# STMP3770 register map
Vendor: Freescale Semiconductor (NXP); Series: STMP37xx; File version: 1.0
CPU: other r0p0, little endian, no MPU, no FPU, 2 interrupt priority bits
Registers are 32-bit, read-write, reset 0x0 unless marked. A register's access mark holds for its fields unless they carry their own. Offsets are from the block's base; [hi:lo] are bit positions; {n}, {i} and the like mark numbered series; 'fields as' and 'values as' point back to an identical list.

## APBH — AHB-to-APBH 桥 DMA 控制器(为 GPMI/NAND、LCDIF 等高速外设提供 DMA 通道)
Base 0x80004000
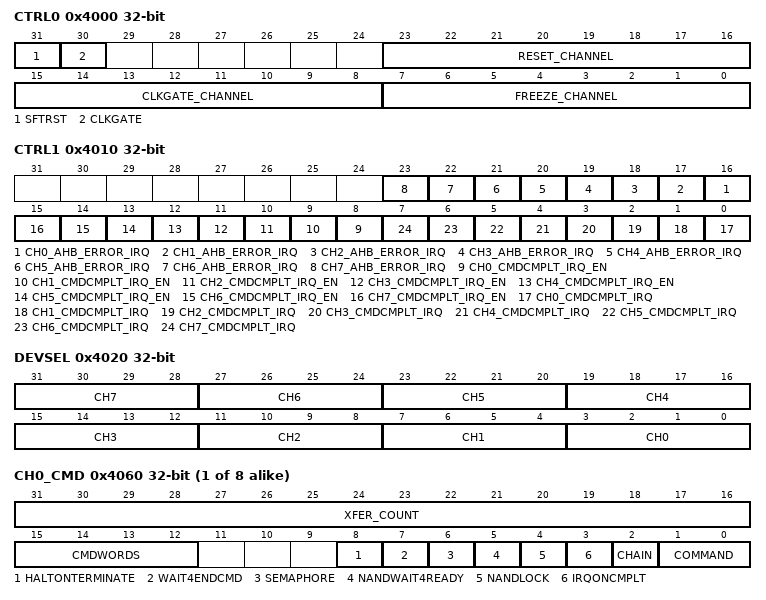
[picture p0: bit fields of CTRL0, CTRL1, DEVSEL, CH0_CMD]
0x4000 CTRL0 — AHB to APBH Bridge Control and Status Register 0
  [31] SFTRST — 软复位控制位，写1复位本模块，写0恢复正常运行。复位后所有寄存器回到默认值。
  [30] CLKGATE — 时钟门控控制位，写1关闭模块时钟以节省功耗，配置状态保持。写0恢复正常时钟供应。
  [23:16] RESET_CHANNEL — Reset Channel，8位读写字段。
    1=LCDIF; 2=SSP1; 4=SSP2; 16=ATA; 32=NAND1; 64=NAND2; 128=NAND3
  [15:8] CLKGATE_CHANNEL — Clkgate Channel，8位读写字段。
    values as RESET_CHANNEL
  [7:0] FREEZE_CHANNEL — Freeze Channel，8位读写字段。
    values as RESET_CHANNEL
0x4010 CTRL1 — AHB to APBH Bridge Control and Status Register 1
  [n+16] CH{n}_AHB_ERROR_IRQ (n=0..7) — Ch{n} Ahb Error Irq，1位读写字段。
  [n+8] CH{n}_CMDCMPLT_IRQ_EN (n=0..7) — Ch{n} Cmdcmplt Irq En，1位读写字段。
  [n] CH{n}_CMDCMPLT_IRQ (n=0..7) — Ch{n} Cmdcmplt Irq，1位读写字段。
0x4020 DEVSEL — AHB to APBH DMA Device Assignment Register
  [4n+3:4n] CH{n} ro (n=0..7) — CH{n} 通道设备分配只读值，反映复位固定的 DMA 通道到外设的分配关系。PDF 标记为 RO/保留。
{0x4040+0x70*i} CH{i}_CURCMDAR (i=0..7) ro — DMA 通道当前命令描述符物理地址(只读,DMA 引擎执行时自动更新)。
  [31:0] CMD_ADDR — 当前命令描述符的 32 位物理地址。
{0x4050+0x70*i} CH{i}_NXTCMDAR (i=0..7) — DMA 通道下一命令描述符物理地址(读写,软件写入待执行描述符链首地址)。
  [31:0] CMD_ADDR — 下一命令描述符的 32 位物理地址。
{0x4060+0x70*i} CH{i}_CMD (i=0..7) ro — DMA 通道当前命令字(只读,镜像正在执行描述符的 CMD 字)。
  [31:16] XFER_COUNT — 本次 DMA 传输字节数。
  [15:12] CMDWORDS — 随描述符的 PIO 字数。
  [8] HALTONTERMINATE — 置位则在终止时停在当前描述符。
  [7] WAIT4ENDCMD — 置位则等待外设结束命令握手后再推进描述符。
  [6] SEMAPHORE — 置位则完成后递减通道信号量。
  [5] NANDWAIT4READY — 置位则等待 NAND R/B 就绪信号后再继续。
  [4] NANDLOCK — 置位则把 GPMI 锁定给本通道直到解锁。
  [3] IRQONCMPLT — 置位则描述符完成后产生通道命令完成中断。
  [2] CHAIN — 置位则完成后继续取 NEXT 指向的下一描述符。
  [1:0] COMMAND — 传输方向：0=不传输，1=外设→内存(DMA_WRITE)，2=内存→外设(DMA_READ)，3=条件分支(DMA_SENSE)。
{0x4070+0x70*i} CH{i}_BAR (i=0..7) ro — DMA 通道缓冲区基址(只读,镜像当前描述符的负载缓冲物理地址)。
  [31:0] ADDRESS — 负载缓冲的 32 位物理地址。
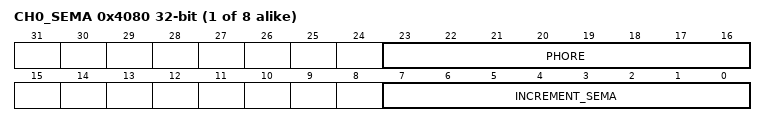
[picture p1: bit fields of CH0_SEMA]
{0x4080+0x70*i} CH{i}_SEMA (i=0..7) — DMA 通道信号量寄存器(读写,写 INCREMENT_SEMA 踢启动传输,读 PHORE 取剩余待处理描述符数)。
  [23:16] PHORE — 当前信号量计数(只读),为剩余尚未完成的描述符个数。
  [7:0] INCREMENT_SEMA — 写入的值累加到通道信号量,等于排队待执行的描述符个数;非零即启动 DMA。
{0x4090+0x70*i} CH{i}_DEBUG1 (i=0..7) ro — DMA 通道调试寄存器 1(只读,含状态机、FIFO 与命令状态)。
{0x40A0+0x70*i} CH{i}_DEBUG2 (i=0..7) ro — DMA 通道调试寄存器 2(只读,含 AHB/APB 已传输字节数)。

## EMI — 外部存储器接口控制器(EMI,SDRAM/mDDR 时钟与读写时序配置)
Base 0x80020000
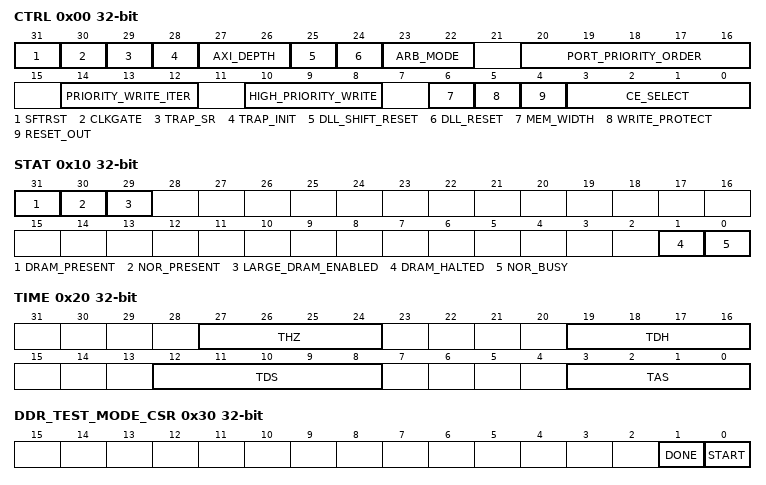
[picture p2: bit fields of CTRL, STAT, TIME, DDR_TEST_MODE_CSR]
0x00 CTRL — EMI Control Register
  [31] SFTRST — 软复位控制位，写1复位本模块，写0恢复正常运行。复位后所有寄存器回到默认值。
  [30] CLKGATE — 时钟门控控制位，写1关闭模块时钟以节省功耗，配置状态保持。写0恢复正常时钟供应。
  [29] TRAP_SR — Trap Sr，1位读写字段。
  [28] TRAP_INIT — Trap Init，1位读写字段。
  [27:26] AXI_DEPTH — Axi Depth，2位读写字段。
    0=ONE; 1=TWO; 2=THREE; 3=FOUR
  [25] DLL_SHIFT_RESET — Dll Shift Reset，1位读写字段。
  [24] DLL_RESET — Dll Reset，1位读写字段。
  [23:22] ARB_MODE — Arb Mode，2位读写字段。
    0=TIMESTAMP; 1=WRITE_HYBRID; 2=PORT_PRIORITY
  [20:16] PORT_PRIORITY_ORDER — Port Priority Order，5位读写字段。
    0=PORT0123; 1=PORT0312; 2=PORT0231; 3=PORT0321; 4=PORT0213; 5=PORT0132; 6=PORT1023; 7=PORT1302; 8=PORT1230; 9=PORT1320; 10=PORT1203; 11=PORT1032; 12=PORT2013; 13=PORT2301; 14=PORT2130; 15=PORT2310; 16=PORT2103; 17=PORT2031; 18=PORT3012; 19=PORT3201; 20=PORT3120; 21=PORT3210; 22=PORT3102; 23=PORT3021
  [14:12] PRIORITY_WRITE_ITER — Priority Write Iter，3位读写字段。
  [10:8] HIGH_PRIORITY_WRITE — High Priority Write，3位读写字段。
  [6] MEM_WIDTH — Mem Width，1位读写字段。
  [5] WRITE_PROTECT — Write Protect，1位读写字段。
  [4] RESET_OUT — Reset Out，1位读写字段。
  [3:0] CE_SELECT — Ce Select，4位读写字段。
    0=NONE; 1=CE0; 2=CE1; 4=CE2; 8=CE3
0x10 STAT — NOR Flash Status Register
  [31] DRAM_PRESENT — Dram Present，1位读写字段。
  [30] NOR_PRESENT — Nor Present，1位读写字段。
  [29] LARGE_DRAM_ENABLED — Large Dram Enabled，1位读写字段。
  [1] DRAM_HALTED — Dram Halted，1位读写字段。
    0=NOT_HALTED; 1=HALTED
  [0] NOR_BUSY — Nor Busy，1位读写字段。
    0=NOT_BUSY; 1=BUSY
0x20 TIME — NOR Flash Memory Timing Control Register
  [27:24] THZ — Thz，4位读写字段。
  [19:16] TDH — Tdh，4位读写字段。
  [12:8] TDS — Tds，5位读写字段。
  [3:0] TAS — Tas，4位读写字段。
0x30 DDR_TEST_MODE_CSR — DDR Test Mode Control and Status Register
  [1] DONE — Done，1位读写字段。
  [0] START — Start，1位读写字段。
0x80 DEBUG ro — NOR Flash Debug Register
  [3:0] NOR_STATE — Nor State，4位读写字段。
0x90 DDR_TEST_MODE_STATUS0 — DDR Test Mode Status Register 0
  [12:0] ADDR0 — Addr0，13位读写字段。
0xA0 DDR_TEST_MODE_STATUS1 — DDR Test Mode Status Register 1
  [12:0] ADDR1 — Addr1，13位读写字段。
0xB0 DDR_TEST_MODE_STATUS2 — DDR Test Mode Status Register 2
  [31:0] DATA0 — Data0，32位读写字段。
0xC0 DDR_TEST_MODE_STATUS3 — DDR Test Mode Status Register 3
  [31:0] DATA1 — Data1，32位读写字段。
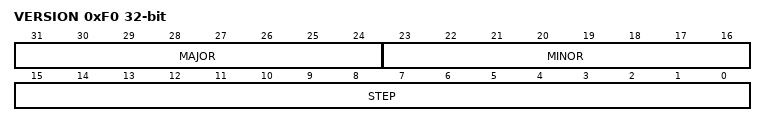
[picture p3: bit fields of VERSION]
0xF0 VERSION ro — EMI Version Register
  [31:24] MAJOR — Major，8位读写字段。
  [23:16] MINOR — Minor，8位读写字段。
  [15:0] STEP — Step，16位读写字段。
